# CC2340R5 register map
File version: 1.0
CPU: CM0P 1.0, other endian, MPU, FPU, 3 interrupt priority bits
Registers are 32-bit, read-write, reset 0x0 unless marked. A register's access mark holds for its fields unless they carry their own. Offsets are from the block's base; [hi:lo] are bit positions; {n}, {i} and the like mark numbered series; 'fields as' and 'values as' point back to an identical list.

## LGPT0 — This component is a general purpose timer. The timer offers - generation of waveforms and events. - capture of signal period and duty cycle. - generation of IR signals. - decoding of quadrature encoded signals. - motor control features. It consists of a - 16-bit counter. - 8-bit prescaler - 3 capture compare channels. - 3 event outputs. - 3 capture inputs. Each channel subscribes to the synchronous event bus. They can control one or more event outputs in both capture and compare modes. PRECFG.TICKSRC selects tick source for the timer.
Base 0x40060000
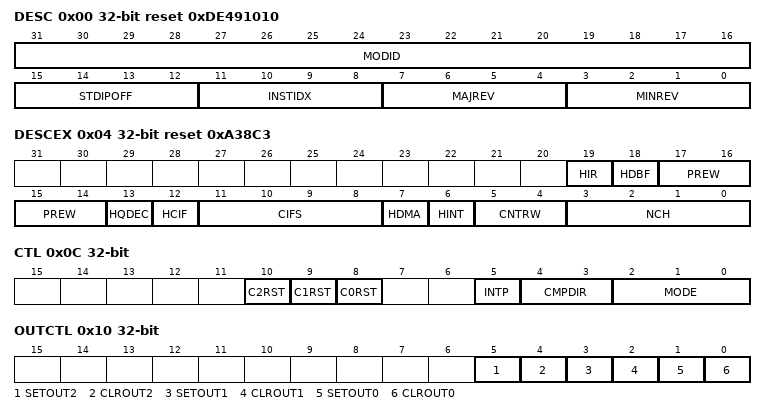
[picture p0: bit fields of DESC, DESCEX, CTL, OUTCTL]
0x00 DESC reset 0xDE491010 — Description Register. This register provides IP module ID, revision information, instance index and standard MMR registers offset.
  [31:16] MODID ro — [31:16] Module identifier used to uniquely identify this IP.
  [15:12] STDIPOFF ro — [15:12] Standard IP MMR block offset. Standard IP MMRs are the set of from aggregated IRQ registers till DTB. 0: Standard IP MMRs do not exist 0x1-0xF: Standard IP MMRs begin at offset of (64*STDIPOFF from the base IP address)
  [11:8] INSTIDX ro — [11:8] IP Instance ID number. If multiple instances of IP exist in the device, this field can identify the instance number.
  [7:4] MAJREV ro — [7:4] Major revision of IP.
  [3:0] MINREV ro — [3:0] Minor revision of IP.
0x04 DESCEX reset 0xA38C3 — Description Extended This register describes the parameters of the LGPT.
  [19] HIR ro — [19:19] Has IR logic.
  [18] HDBF ro — [18:18] Has Dead-Band, Fault, and Park logic.
  [17:14] PREW ro — [17:14] Prescale width. The prescaler can maximum be configured to 2^PREW-1.
  [13] HQDEC ro — [13:13] Has Quadrature Decoder.
  [12] HCIF ro — [12:12] Has channel input filter.
  [11:8] CIFS ro — [11:8] Channel input filter size. The prevailing state filter can maximum be configured to 2^CIFS-1.
  [7] HDMA ro — [7:7] Has uDMA output and logic.
  [6] HINT ro — [6:6] Has interrupt output and logic.
  [5:4] CNTRW ro — [5:4] Counter bit-width. The maximum counter value is equal to 2^CNTRW-1.
    2=CNTR32 (32-bit counter.); 1=CNTR24 (24-bit counter.); 0=CNTR16 (16-bit counter.)
  [3:0] NCH ro — [3:0] Number of channels.
0x08 STARTCFG — Start Configuration This register is only for when CTL.MODE is configured to one of the SYNC modes. This register defines when this LGPT starts.
  [1:0] LGPT0 — [1:0] LGPT start
    0=EV_SYNC (LGPT starts when synchronized event input is high. Configured here EVTSVT.LGPTSYNCSEL.)
0x0C CTL — Timer Control
  [10] C2RST wo — [10:10] Channel 2 reset.
    1=RST (Reset C2CC, PC2CC, and C2CFG.); 0=NOEFF (No effect.)
  [9] C1RST wo — [9:9] Channel 1 reset.
    1=RST (Reset C1CC, PC1CC, and C1CFG.); 0=NOEFF (No effect.)
  [8] C0RST wo — [8:8] Channel 0 reset.
    1=RST (Reset C0CC, PC0CC, and C0CFG.); 0=NOEFF (No effect.)
  [5] INTP — [5:5] Interrupt Phase. This bit field controls when the RIS.TGT and RIS.ZERO interrupts are set.
    1=LATE (RIS.TGT and RIS.ZERO are set one timer clock cycle after CNTR = TARGET/ZERO.); 0=EARLY (RIS.TGT and RIS.ZERO are set one system clock cycle after CNTR = TARGET/ZERO.)
  [4:3] CMPDIR — [4:3] Compare direction. This bit field controls the direction the counter must have in order to set the RIS compare interrupts.
    2=DOWN (Compare RIS fields are only set on down count.); 1=UP (Compare RIS fields are only set on up count.); 0=BOTH (Compare RIS fields are set on up count and down count.)
  [2:0] MODE — [2:0] Timer mode control The CNTR restarts from 0 when MODE is written to UP_ONCE, UP_PER, UPDWN_PER, QDEC, SYNC_UP_ONCE, SYNC_UP_PER or SYNC_UPDWN_PER. When writing MODE all internally queued updates to the channels and TGT is cleared. When configuring the timer, MODE should be the last thing to configure. If changing timer configuration after MODE has been set is necessary, instructions, if any, given in the configuration registers should be followed. See for example C0CFG.
    7=SYNC_UPDWN_PER (Start counting up and down periodically synchronous to another LGPT, selected within STARTCFG. The timer is started by setting CTL.MODE = UPDWN_PER automatically. It then operates as a normal timer in CTL.MODE = UPDWN_PER, counting from 0 to target value and back to 0, repeatedly. Period = (target value * 2) * timer clock period); 6=SYNC_UP_PER (Start counting up periodically synchronous to another LGPT, selected within STARTCFG. The timer is started by setting CTL.MODE = UP_PER automatically. It then operates as a normal timer in CTL.MODE = UP_PER, incrementing from 0 to target value, repeatedly. Period = (target value * 2) * timer clock period); 5=SYNC_UP_ONCE (Start counting up once synchronous to another LGPT, selected within STARTCFG. The timer is started by setting CTL.MODE = UP_ONCE automatically. It then functions as a normal timer in CTL.MODE = UP_ONCE, incrementing from 0 to target value, then stops and sets MODE to DIS.); 4=QDEC (The timer functions as a quadrature decoder. IOC input 0, IOC input 1 and IOC input 2 are used respectivly as PHA, PHB and IDX inputs. IDX can be turned off by setting C2CFG.EDGE = NONE. The timer clock frequency sets the sample rate of the QDEC logic. This frequency can be configured in PRECFG.); 3=UPDWN_PER (Count up and down periodically. The timer counts from 0 to target value and back to 0, repeatedly. Period = (target value * 2) * timer clock period); 2=UP_PER (Count up periodically. The timer increments from 0 to target value, repeatedly. Period = (target value + 1) * timer clock period); 1=UP_ONCE (Count up once. The timer increments from 0 to target value, then stops and sets MODE to DIS.); 0=DIS (Disable timer. Updates to counter, channels, and events stop.)
0x10 OUTCTL — Output Control Set and clear individual outputs manually. Manual update of an output takes priority over automatic channel updates to the same output. It is not possible to set and clear an output at the same time, such requests will be neglected. An output can be automatically cleared, set, toggled, or pulsed by each channel, listed in decreasing order of priority. The action with highest priority happens when multiple channels want to update an output at the same time. All outputs are connected to the event fabric and the IO controller. The outputs going to the IO controller have an aditional complementary output, this output is the inverted IO output. Both the IO and the IO complementary outputs are passed through an IO Controller, see IOCTL.
  [5] SETOUT2 wo — [5:5] Set output 2. Write 1 to set output 2.
  [4] CLROUT2 wo — [4:4] Clear output 2. Write 1 to clear output 2.
  [3] SETOUT1 wo — [3:3] Set output 1. Write 1 to set output 1.
  [2] CLROUT1 wo — [2:2] Clear output 1. Write 1 to clear output 1.
  [1] SETOUT0 wo — [1:1] Set output 0. Write 1 to set output 0.
  [0] CLROUT0 wo — [0:0] Clear output 0. Write 1 to clear output 0.
0x14 CNTR — Counter The counter of this timer. After CTL.MODE is set the counter updates at the rate specified in PRECFG.
  [15:0] VAL — [15:0] Current counter value. If CTL.MODE = QDEC this can be used to set the initial counter value during QDEC.
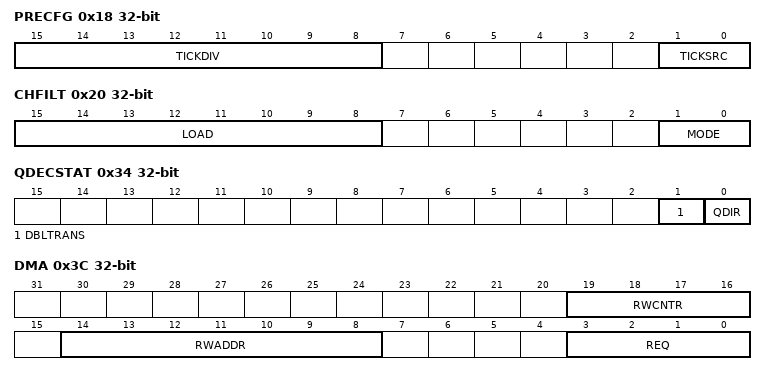
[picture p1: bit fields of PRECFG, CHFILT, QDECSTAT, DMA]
0x18 PRECFG — Clock Prescaler Configuration This register is used to set the timer clock period. The prescaler is a counter which counts down from the value TICKDIV. When the prescaler counter reaches zero, CNTR is updated. The field TICKDIV effectively divides the prescaler tick source. The timer clock frequency can be calculated as TICKSRC/(TICKDIV+1).
  [15:8] TICKDIV — [15:8] Tick division. TICKDIV determines the timer clock frequency for the counter, and timer output updates. The timer clock frequency is the clock selected by TICKSRC divided by (TICKDIV + 1). This inverse is the timer clock period. 0x00: Divide by 1. 0x01: Divide by 2. ... 0xFF: Divide by 256.
  [1:0] TICKSRC — [1:0] Prescaler tick source. TICKSRC determines the source which decrements the prescaler.
    3=BOTH_TICK (Prescaler is updated at both edges of TICKEN.); 2=FALL_TICK (Prescaler is updated at the falling edge of TICKEN.); 1=RISE_TICK (Prescaler is updated at the rising edge of TICKEN.); 0=CLK (Prescaler is updated at the system clock.)
0x1C PREEVENT — Prescaler Event This register is used to output a logic high signal before the zero crossing of the prescaler counter. The output is routed to the IOC.
  [7:0] VAL — [7:0] Sets the HIGH time of the prescaler event output. Event goes high when the prescaler counter equals VAL. Event goes low when prescaler counter is 0. Note: - Can be used to precharge or turn an external component on for a short time before sampling, like in QDEC. - If there is a requirement to create such events that have very short periods compared to timer clock period, use two timers. One timer acts as prescaler and event generator for another timer.
0x20 CHFILT — Channel Input Filter This register is used to configure the filter on the channel inputs. The configuration is for all inputs. The filter is enabled when a channel is in capture mode. The input to the filter is passed to the edge detection logic if LOAD + 1 consecutive input samples are equal. The filter functions as a down counter, counting down every input sample. If two consecutive samples are unequal, the filter counter restarts from LOAD. If the filter counter reaches zero, the input signal is valid and passed to the edge detection logic. The channel filter should only be configured while the CTL.MODE = DIS. Configuring the filter while the timer is running can result in unexpected behavior.
  [15:8] LOAD — [15:8] The input of the channel filter is passed to the edge detection logic after LOAD + 1 consecutive equal samples.
  [1:0] MODE — [1:0] Channel filter mode
    3=TIMERCLK (Filter is clocked by timer clock.); 2=TICKSRC (Filter is clocked by PRECFG.TICKSRC.); 1=CLK (Filter is clocked by system clock.); 0=BYPASS (Filter is bypassed. No Filter is used.)
0x34 QDECSTAT — Quadrature Decoder Status This register can be used during QDEC mode to check the status of the quadrature decoder.
  [1] DBLTRANS ro — [1:1] Double transition
    1=DBL (Double transition on phase inputs.); 0=NONE (Single or no transition on phase inputs.)
  [0] QDIR ro — [0:0] Direction of count during QDEC mode.
    1=DOWN (Down (PHB leads PHA)); 0=UP (Up (PHA leads PHB))
0x38 IRGEN — IR Generation Use this register to generate IR codes. When CTL = 1, an AND gate is enabled between IO output 0 in LGPT0 and IC output 0 in LGPT1. The output of the gate overrides IO output 0 in LGPT0. See OUTCTL for explanation of outputs. To generate IR codes let LGPT0 generate the carrier wave on output 0. Set this output as tick input of LGPT1, with PRECFG.TICKSRC = FALL_TICK. Generate wanted IR codes by adjusting LGPT1 PTGT and PC0CC.
  [0] CTL — [0:0] Control
    1=EN (Enable.); 0=DIS (Disable.)
0x3C DMA — Direct Memory Accsess This register is used to enable DMA requests from the timer and set the register addresses which the DMA will access (read/write). Choose DMA request source by setting the REQ field. The setting of the corresponding interrupt in the RIS registers also sets the DMA request. Upon a DMA request defined by REQ an internal address pointer is set to RWADDR*4. Every access to DMARW will increment the internal pointer by 4 such that the next DMA access will be to the next register. The internal pointer will stop after RWCNTR increments. Further access will be ignored.
  [19:16] RWCNTR — [19:16] The read/write counter. RWCNTR+1 is the number of times the DMA can access (read/write) the DMARW register. For each DMA access to DMARW an internal counter is incremented, writing to the next address field. RWADDR + 4*RWCNTR is the final register address which can be accessed by the DMA.
  [14:8] RWADDR — [14:8] The base address which the DMA access when reading/writing DMARW. The base address is set by taking the 9 LSB of the physical address and divide by 4. For example, if you wanted the RWADDR to point to the PTGT register you should set RWADDR = 0x0FC/4.
  [3:0] REQ
    {v}=C{v-4}CC (Setting of RIS.C{v-4}CC generates a DMA request.) (v=4..15); 3=FAULT (Setting of RIS.FAULT generates a DMA request.); 2=ZERO (Setting of RIS.ZERO generates a DMA request.); 1=TGT (Setting of RIS.TGT generates a DMA request.); 0=DIS (Disabled)
0x40 DMARW — Direct Memory Access This register is used by the DMA to access (read/write) register inside this LGPT module. Each access to this register will increment the internal DMA address counter. See DMA for description.
  [15:0] VAL — [15:0] DMA read write value. The value that is read/written from/to the registers.
0x44 ADCTRG — ADC Trigger This register is used to enable ADC trigger from the timer. Choose ADC trigger source by setting the SRC field. The setting of the corresponding interrupt in the RIS registers also sets the ADC trigger.
  [3:0] SRC
    {v}=C{v-4}CC (Setting of RIS.C{v-4}CC generates an ADC trigger.) (v=4..15); 3=FAULT (Setting of RIS.FAULT generates an ADC trigger.); 2=ZERO (Setting of RIS.ZERO generates an ADC trigger.); 1=TGT (Setting of RIS.TGT generates an ADC trigger.); 0=DIS (Disabled)
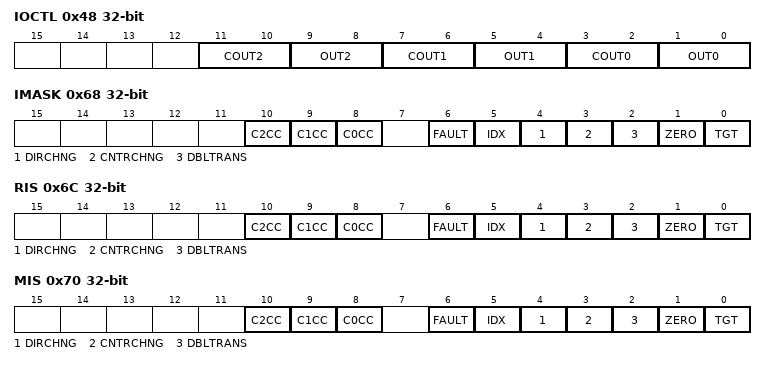
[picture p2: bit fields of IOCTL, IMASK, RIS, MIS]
0x48 IOCTL — IO Controller This register controls the IO outputs.
  [11:10] COUT2 — [11:10] IO complementary output 2 control This bit field controls IO complementary output 2.
    3=INV (Inverted value. The IO complementary output is inverted.); 2=HIGH (Driven high. The IO complementary output is driven high.); 1=LOW (Driven low. The IO complementary output is driven low.); 0=NRM (Normal output. The IO complementary output is not changed.)
  [9:8] OUT2 — [9:8] IO output 2 control This bit field controls IO output 2.
    3=INV (Inverted value. The IO output is inverted.); 2=HIGH (Driven high. The IO output is driven high.); 1=LOW (Driven low. The IO output is driven low.); 0=NRM (Normal output. The IO output is not changed.)
  [7:6] COUT1 — [7:6] IO complementary output 1 control This bit field controls IO complementary output 1.
    values as COUT2
  [5:4] OUT1 — [5:4] IO output 1 control This bit field controls IO output 1.
    values as OUT2
  [3:2] COUT0 — [3:2] IO complementary output 0 control This bit field controls IO complementary output 0.
    values as COUT2
  [1:0] OUT0 — [1:0] IO output 0 control This bit field controls IO output 0.
    values as OUT2
0x68 IMASK — Interrupt mask. This register selects interrupt sources which are allowed to pass from RIS to MIS when the corresponding bit-fields are set to 1.
  [all] fields
    1=EN (Enable); 0=DIS (Disable)
  [10] C2CC — [10:10] Enable RIS.C2CC interrupt.
  [9] C1CC — [9:9] Enable RIS.C1CC interrupt.
  [8] C0CC — [8:8] Enable RIS.C0CC interrupt.
  [6] FAULT — [6:6] Enable RIS.FAULT interrupt.
  [5] IDX — [5:5] Enable RIS.IDX interrupt.
  [4] DIRCHNG — [4:4] Enable RIS.DIRCHNG interrupt.
  [3] CNTRCHNG — [3:3] Enable RIS.CNTRCHNG interrupt.
  [2] DBLTRANS — [2:2] Enable RIS.DBLTRANS interrupt.
  [1] ZERO — [1:1] Enable RIS.ZERO interrupt.
  [0] TGT — [0:0] Enable RIS.TGT interrupt.
0x6C RIS — Raw interrupt status. This register reflects the state of all pending interrupts, regardless of masking. This register allows the user to implement a poll scheme. A flag set in this register can be cleared by writing 1 to the corresponding ICLR register bit.
  [all] fields
    1=SET; 0=CLR (Cleared)
  [10] C2CC ro — [10:10] Status of the C2CC interrupt. The interrupt is set when C2CC has capture or compare event.
  [9] C1CC ro — [9:9] Status of the C1CC interrupt. The interrupt is set when C1CC has capture or compare event.
  [8] C0CC ro — [8:8] Status of the C0CC interrupt. The interrupt is set when C0CC has capture or compare event.
  [6] FAULT ro — [6:6] Status of the FAULT interrupt. The interrupt is set immediately on active fault input.
  [5] IDX ro — [5:5] Status of the IDX interrupt. The interrupt is set when IDX is active.
  [4] DIRCHNG ro — [4:4] Status of the DIRCHNG interrupt. The interrupt is set when the direction of the counter changes.
  [3] CNTRCHNG ro — [3:3] Status of the CNTRCHNG interrupt. The interrupt is set when the counter increments or decrements.
  [2] DBLTRANS ro — [2:2] Status of the DBLTRANS interrupt. The interrupt is set when a double transition has happened during QDEC mode.
  [1] ZERO ro — [1:1] Status of the ZERO interrupt. The interrupt is set when CNTR = 0.
  [0] TGT ro — [0:0] Status of the TGT interrupt. The interrupt is set when CNTR = TGT.
0x70 MIS — Masked interrupt status. This register is simply a bitwise AND of the contents of IMASK and RIS.*] registers. A flag set in this register can be cleared by writing 1 to the corresponding ICLR register bit.
  [all] fields
    1=SET; 0=CLR (Cleared)
  [10] C2CC ro — [10:10] Masked status of the RIS.C2CC interrupt.
  [9] C1CC ro — [9:9] Masked status of the RIS.C1CC interrupt.
  [8] C0CC ro — [8:8] Masked status of the RIS.C0CC interrupt.
  [6] FAULT ro — [6:6] Masked status of the RIS.FAULT interrupt.
  [5] IDX ro — [5:5] Masked status of the RIS.IDX interrupt.
  [4] DIRCHNG ro — [4:4] Masked status of the RIS.DIRCHNG interrupt.
  [3] CNTRCHNG ro — [3:3] Masked status of the RIS.CNTRCHNG interrupt.
  [2] DBLTRANS ro — [2:2] Masked status of the RIS.DBLTRANS interrupt.
  [1] ZERO ro — [1:1] Masked status of the RIS.ZERO interrupt.
  [0] TGT ro — [0:0] Masked status of the RIS.TGT interrupt.
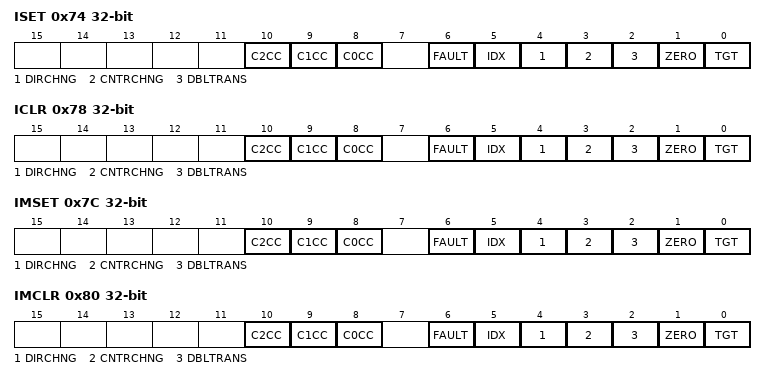
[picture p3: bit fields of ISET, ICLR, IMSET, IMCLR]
0x74 ISET — Interrupt set register. This register can used by software for diagnostics and safety checking purposes. Writing a 1 to a bit in this register will set the event and the corresponding RIS bit also gets set. If the corresponding IMASK bit is set, then the corresponding MIS register bit also gets set.
  [all] fields
    1=SET; 0=NO_EFFECT
  [10] C2CC wo — [10:10] Set the RIS.C2CC interrupt.
  [9] C1CC wo — [9:9] Set the RIS.C1CC interrupt.
  [8] C0CC wo — [8:8] Set the RIS.C0CC interrupt.
  [6] FAULT wo — [6:6] Set the RIS.FAULT interrupt.
  [5] IDX wo — [5:5] Set the RIS.IDX interrupt.
  [4] DIRCHNG wo — [4:4] Set the RIS.DIRCHNG interrupt.
  [3] CNTRCHNG wo — [3:3] Set the RIS.CNTRCHNG interrupt.
  [2] DBLTRANS wo — [2:2] Set the RIS.DBLTRANS interrupt.
  [1] ZERO wo — [1:1] Set the RIS.ZERO interrupt.
  [0] TGT wo — [0:0] Set the RIS.TGT interrupt.
0x78 ICLR — Interrupt clear register. This register allows software to clear interrupts. Writing a 1 to a bit in this register will clear the event and the corresponding RIS bit also gets cleared. If the corresponding IMASK bit is set, then the corresponding MIS register bit also gets cleared.
  [all] fields
    1=CLR (Clear); 0=NO_EFFECT
  [10] C2CC wo — [10:10] Clear the RIS.C2CC interrupt.
  [9] C1CC wo — [9:9] Clear the RIS.C1CC interrupt.
  [8] C0CC wo — [8:8] Clear the RIS.C0CC interrupt.
  [6] FAULT wo — [6:6] Clear the RIS.FAULT interrupt.
  [5] IDX wo — [5:5] Clear the RIS.IDX interrupt.
  [4] DIRCHNG wo — [4:4] Clear the RIS.DIRCHNG interrupt.
  [3] CNTRCHNG wo — [3:3] Clear the RIS.CNTRCHNG interrupt.
  [2] DBLTRANS wo — [2:2] Clear the RIS.DBLTRANS interrupt.
  [1] ZERO wo — [1:1] Clear the RIS.ZERO interrupt.
  [0] TGT wo — [0:0] Clear the RIS.TGT interrupt.
0x7C IMSET — Interrupt mask set register. Writing a 1 to a bit in this register will set the corresponding IMASK bit.
  [all] fields
    1=SET; 0=NO_EFFECT
  [10] C2CC wo — [10:10] Set the MIS.C2CC mask.
  [9] C1CC wo — [9:9] Set the MIS.C1CC mask.
  [8] C0CC wo — [8:8] Set the MIS.C0CC mask.
  [6] FAULT wo — [6:6] Set the MIS.FAULT mask.
  [5] IDX wo — [5:5] Set the MIS.IDX mask.
  [4] DIRCHNG wo — [4:4] Set the MIS.DIRCHNG mask.
  [3] CNTRCHNG wo — [3:3] Set the MIS.CNTRCHNG mask.
  [2] DBLTRANS wo — [2:2] Set the MIS.DBLTRANS mask.
  [1] ZERO wo — [1:1] Set the MIS.ZERO mask.
  [0] TGT wo — [0:0] Set the MIS.TGT mask.
0x80 IMCLR — Interrupt mask clear register. Writing a 1 to a bit in this register will clear the corresponding IMASK bit.
  [all] fields
    1=CLR (Clear); 0=NO_EFFECT
  [10] C2CC wo — [10:10] Clear the MIS.C2CC mask.
  [9] C1CC wo — [9:9] Clear the MIS.C1CC mask.
  [8] C0CC wo — [8:8] Clear the MIS.C0CC mask.
  [6] FAULT wo — [6:6] Clear the MIS.FAULT mask.
  [5] IDX wo — [5:5] Clear the MIS.IDX mask.
  [4] DIRCHNG wo — [4:4] Clear the MIS.DIRCHNG mask.
  [3] CNTRCHNG wo — [3:3] Clear the MIS.CNTRCHNG mask.
  [2] DBLTRANS wo — [2:2] Clear the MIS.DBLTRANS mask.
  [1] ZERO wo — [1:1] Clear the MIS.ZERO mask.
  [0] TGT wo — [0:0] Clear the MIS.TGT mask.
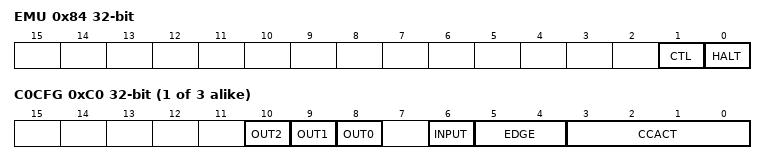
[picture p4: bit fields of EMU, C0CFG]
0x84 EMU — Debug control This register can be used to freeze the timer when CPU halts when HALT is set to 1. When HALT is set to 0, or when the CPU releases debug halt, the filters and edge detection logic is flushed and the timer starts. For setting a predefined output value during a CPU debug halt, PARK, if the timer has this register, should be configured additionally. If this timer does not have the PARK register a predefined output value during CPU halt is not possible.
  [1] CTL — [1:1] Halt control. Configure when the counter shall stop upon CPU halt. This bitfield only applies if HALT = 1.
    1=ZERCOND (Zero condition. The counter stops when CNTR = 0.); 0=IMMEDIATE (Immediate reaction. The counter stops immediately on debug halt.)
  [0] HALT — [0:0] Halt LGPT when CPU is halted in debug.
    1=EN (Enable.); 0=DIS (Disable.)
{0xC0+4i} C{i}CFG (i=0..2) — Channel {i} Configuration This register configures channel function and enables outputs. Each channel has an edge-detection circuit. The the edge-detection circuit is: - enabled while CCACT selects a capture function and CTL.MODE is different from DIS. - flushed while CCACT selects a capture function and CTL.MODE is changed from DIS to another mode. The flush action uses two system clock periods. It prevents capture events caused by expired signal values stored in the edge-detection circuit. The channel input signal enters the edge-detection circuit. False capture events can occur when: - the edge-detection circuit contains expired signal samples and the circuit is enabled without flush as described above. - the CCACT field is reconfigured while CTL.MODE is different from DIS. Primary use scenario is to select CCACT before starting the timer. Follow these steps to configure CCACT to a capture action while CTL.MODE is different from DIS: - Set EDGE to NONE. - Configure CCACT. - Wait for three system clock periods before setting EDGE different from NONE. These steps prevent capture events caused by expired signal values in edge-detection circuit.
  [10] OUT2 — [10:10] Output 2 enable. When 0 $lt; CCACT $lt; 8, OUT2 becomes zero after a capture or compare event.
    1=EN (Channel {i} controls output 2.); 0=DIS (Channel {i} does not control output 2.)
  [9] OUT1 — [9:9] Output 1 enable. When 0 $lt; CCACT $lt; 8, OUT1 becomes zero after a capture or compare event.
    1=EN (Channel {i} controls output 1.); 0=DIS (Channel {i} does not control output 1.)
  [8] OUT0 — [8:8] Output 0 enable. When 0 $lt; CCACT $lt; 8, OUT0 becomes zero after a capture or compare event.
    1=EN (Channel {i} controls output 0.); 0=DIS (Channel {i} does not control output 0.)
  [6] INPUT — [6:6] Select channel input.
    1=IO (IO controller); 0=EV (Event fabric)
  [5:4] EDGE — [5:4] Determines the edge that triggers the channel input event. This happens post filter.
    3=BOTH (Input event is triggered at both edges.); 2=FALL (Input event is triggered at falling edge.); 1=RISE (Input event is triggered at rising edge.); 0=NONE (Input is turned off.)
  [3:0] CCACT — [3:0] Capture-Compare action. Capture-Compare action defines 15 different channel functions that utilize capture, compare, and zero events. In every compare event the timer looks at the current value of CNTR. The corresponding output event will be set 1 timer period after CNTR = C{i}CC.
    15=PULSE_ON_CMP (Pulse on compare repeatedly. Channel function sequence: - Pulse enabled outputs when C{i}CC.VAL = CNTR.VAL. The output is high for two timer clock periods.); 14=TGL_ON_CMP (Toggle on compare repeatedly. Channel function sequence: - Toggle enabled outputs when C{i}CC.VAL = CNTR.VAL.); 13=SET_ON_CMP (Set on compare repeatedly. Channel function sequence: - Set enabled outputs when C{i}CC.VAL = CNTR.VAL.); 12=CLR_ON_CMP (Clear on compare repeatedly. Channel function sequence: - Clear enabled outputs when C{i}CC.VAL = CNTR.VAL.); 11=SET_ON_0_TGL_ON_CMP (Set on zero, toggle on compare repeatedly. Channel function sequence: - Set enabled outputs when CNTR.VAL = 0. - Toggle enabled outputs when C{i}CC.VAL = CNTR.VAL. Set CTL.MODE to UP_PER for edge-aligned PWM generation. Duty cycle is given by: When C{i}CC.VAL $lt;= TGT.VAL: Duty cycle = C{i}CC.VAL / ( TGT.VAL + 1 ). When C{i}CC.VAL $gt; TGT.VAL: Duty cycle = 1. Enabled outputs are cleared when C{i}CC.VAL = 0 and CNTR.VAL = 0.); 10=CLR_ON_0_TGL_ON_CMP (Clear on zero, toggle on compare repeatedly. Channel function sequence: - Clear enabled outputs when CNTR.VAL = 0. - Toggle enabled outputs when C{i}CC.VAL = CNTR.VAL. Set CTL.MODE to UPDWN_PER for center-aligned PWM generation. Duty cycle is given by: When C{i}CC.VAL $lt;= TGT.VAL: Duty cycle = 1 - ( C{i}CC.VAL / TGT.VAL ). When C{i}CC.VAL $gt; TGT.VAL: Duty cycle = 0. Enabled outputs are set when C{i}CC.VAL = 0 and CNTR.VAL = 0.); 9=SET_ON_CAPT (Set on capture repeatedly. Channel function sequence: - Set enabled outputs on capture event and copy CNTR.VAL to C{i}CC.VAL.); 8=PER_PULSE_WIDTH_MEAS (Period and pulse width measurement. Continuously capture period and pulse width of the signal selected by INPUT relative to the signal edge given by EDGE. Set enabled outputs and RIS.C{i}CC when C{i}CC.VAL contains signal period and PC{i}CC.VAL contains signal pulse width. Notes: - Make sure to configure INPUT and CCACT when CTL.MODE equals DIS, then set CTL.MODE to UP_ONCE or UP_PER. - The counter restarts in the selected timer mode when C{i}CC.VAL contains the signal period. - If more than one channel uses this function, the channels will perform this function one at a time. The channel with lowest number has priority and performs the function first. Next measurement starts when current measurement completes successfully or times out. A timeout occurs when counter equals target. - To observe a timeout event the RIS.TGT interrupt can be used, or another channel can be configured to SET_ON_CMP with compare value equal TGT. Signal property requirements: - Signal Period $gt;= 2 * ( 1 + PRECFG.TICKDIV ) * timer clock period. - Signal Period $lt;= MAX(CNTR) * (1 + PRECFG.TICKDIV ) * timer clock period. - Signal low and high phase $gt;= (1 + PRECFG.TICKDIV ) * timer clock period.); 7=PULSE_ON_CMP_DIS (Pulse on compare, and then disable channel. Channel function sequence: - Pulse enabled outputs when C{i}CC.VAL = CNTR.VAL. - Disable channel. The output is high for two timer clock periods.); 6=TGL_ON_CMP_DIS (Toggle on compare, and then disable channel. Channel function sequence: - Toggle enabled outputs when C{i}CC.VAL = CNTR.VAL. - Disable channel.); 5=SET_ON_CMP_DIS (Set on compare, and then disable channel. Channel function sequence: - Set enabled outputs when C{i}CC.VAL = CNTR.VAL. - Disable channel.); 4=CLR_ON_CMP_DIS (Clear on compare, and then disable channel. Channel function sequence: - Clear enabled outputs when C{i}CC.VAL = CNTR.VAL. - Disable channel.); 3=SET_ON_0_TGL_ON_CMP_DIS (Set on zero, toggle on compare, and then disable channel. Channel function sequence: - Set enabled outputs when CNTR.VAL = 0. - Toggle enabled outputs when C{i}CC.VAL = CNTR.VAL. - Disable channel. Enabled outputs are cleared when C{i}CC.VAL = 0 and CNTR.VAL = 0.); 2=CLR_ON_0_TGL_ON_CMP_DIS (Clear on zero, toggle on compare, and then disable channel. Channel function sequence: - Clear enabled outputs when CNTR.VAL = 0. - Toggle enabled outputs when C{i}CC.VAL = CNTR.VAL. - Disable channel. Enabled outputs are set when C{i}CC.VAL = 0 and CNTR.VAL = 0.); 1=SET_ON_CAPT_DIS (Set on capture, and then disable channel. Channel function sequence: - Set enabled outputs on capture event and copy CNTR.VAL to C{i}CC.VAL. - Disable channel. Primary use scenario is to select this function before starting the timer. Follow these steps to select this function while CTL.MODE is different from DIS: - Set CCACT to SET_ON_CAPT with no output enable. - Configure INPUT (optional). - Wait for three timer clock periods as defined in PRECFG before setting CCACT to SET_ON_CAPT_DIS. Output enable is optional. These steps prevent capture events caused by expired signal values in edge-detection circuit.); 0=DIS (Disable channel.)
0xFC PTGT — Pipeline Target A read or write to this register will clear the RIS.ZERO and RIS.TGT interrupt. If CTL.MODE != QDEC. Target value for next counter period. The timer will copy PTGT.VAL to TGT.VAL on the upcoming CNTR zero crossing only if PTGT.VAL has been written. The copy does not happen when restarting the timer. This is useful to avoid period jitter in PWM applications with time-varying period, sometimes referenced as phase corrected PWM. If CTL.MODE = QDEC The CNTR value is updated with VALUE on IDX if the counter is counting down. If the counter is counting up, CNTR is loaded with zero on IDX. In this mode the VALUE is not loaded into TGT on zero crossing.
  [15:0] VAL — [15:0] The pipleline target value.
{0x100+4i} PC{i}CC (i=0..2) — Pipeline Channel {i} Capture Compare
  [15:0] VAL — [15:0] Pipeline Capture Compare value. User defined pipeline compare value or channel-updated capture value. A read or write to this register will clear the RIS.C{i}CC interrupt. Compare mode: An update of VAL will be transferred to C{i}CC.VAL when the next CNTR.VAL is zero and CTL.MODE is different from DIS. This is useful for PWM generation and prevents jitter on the edges of the generated signal. Capture mode: When C{i}CFG.CCACT equals PER_PULSE_WIDTH_MEAS then VAL contains the width of the low or high phase of the selected signal. This is specified by C{i}CFG.EDGE.
0x13C TGT reset 0xFFFF — Target User defined counter target. A read or write to this register will clear the RIS.ZERO and RIS.TGT interrupt.
  [15:0] VAL — [15:0] User defined counter target value.
{0x140+4i} C{i}CC (i=0..2) — Channel {i} Capture Compare
  [15:0] VAL — [15:0] Capture Compare value. User defined compare value or channel-updated capture value. A read or write to this register will clear the RIS.C{i}CC interrupt. Compare mode: VAL is compared against CNTR.VAL and an event is generated as specified by C{i}CFG.CCACT when these are equal. Capture mode: The current counter value is stored in VAL when a capture event occurs. C{i}CFG.CCACT determines if VAL is a signal period or a regular capture value.
0x17C PTGTNC — Pipeline Target No Clear Use this register to read or write to PTGT without clearing the RIS.ZERO and RIS.TGT interrupt.
  [15:0] VAL — [15:0] A read or write to this register will not clear the RIS.TGT interrupt. If CTL.MODE != QDEC. Target value for next counter period. The timer copies VAL to TGT.VAL when CNTR.VAL becomes 0. The copy does not happen when restarting the timer. This is useful to avoid period jitter in PWM applications with time-varying period, sometimes referenced as phase corrected PWM. If CTL.MODE = QDEC. The CNTR.VAL is updated with VAL on IDX. VAL is not loaded into TGT.VAL when CNTR.VAL becomes 0.
{0x180+4i} PC{i}CCNC (i=0..2) — Pipeline Channel {i} Capture Compare No Clear
  [15:0] VAL — [15:0] Pipeline Capture Compare value. User defined pipeline compare value or channel-updated capture value. A read or write to this register will not clear the RIS.C{i}CC interrupt. Compare mode: An update of VAL will be transferred to C{i}CC.VAL when the next CNTR.VAL is zero and CTL.MODE is different from DIS. This is useful for PWM generation and prevents jitter on the edges of the generated signal. Capture mode: When C{i}CFG.CCACT equals PER_PULSE_WIDTH_MEAS then VAL contains the width of the low or high phase of the selected signal. This is specified by C{i}CFG.EDGE.
0x1BC TGTNC reset 0xFFFF — Target No Clear Use this register to read or write to TGT without clearing the RIS.ZERO and RIS.TGT interrupt.
  [15:0] VAL — [15:0] User defined counter target value.
{0x1C0+4i} C{i}CCNC (i=0..2) — Channel {i} Capture Compare No Clear
  [15:0] VAL — [15:0] Capture Compare value. User defined compare value or channel-updated capture value. A read or write to this register will not clear the RIS.C{i}CC interrupt. Compare mode: VAL is compared against CNTR.VAL and an event is generated as specified by C{i}CFG.CCACT when these are equal. Capture mode: The current counter value is stored in VAL when a capture event occurs. C{i}CFG.CCACT determines if VAL is a signal period or a regular capture value.

## LGPT1 — This component is a general purpose timer. The timer offers - generation of waveforms and events. - capture of signal period and duty cycle. - generation of IR signals. - decoding of quadrature encoded signals. - motor control features. It consists of a - 16-bit counter. - 8-bit prescaler - 3 capture compare channels. - 3 event outputs. - 3 capture inputs. Each channel subscribes to the synchronous event bus. They can control one or more event outputs in both capture and compare modes. PRECFG.TICKSRC selects tick source for the timer.
Base 0x40061000
Registers as LGPT0, without QDECSTAT, IRGEN; these are added or differ:
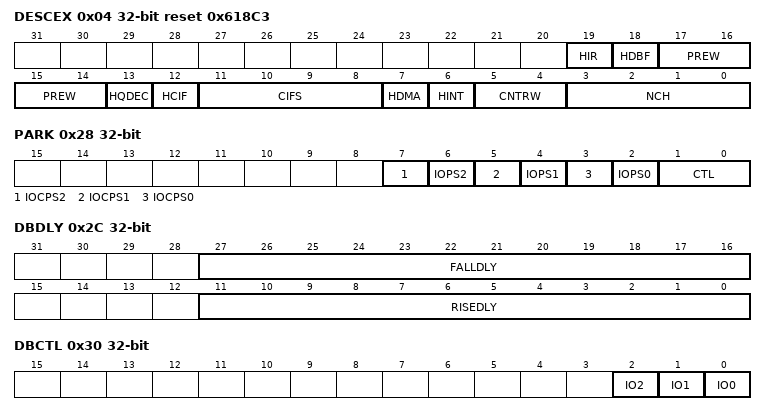
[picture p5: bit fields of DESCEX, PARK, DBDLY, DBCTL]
0x04 DESCEX reset 0x618C3 — Description Extended This register describes the parameters of the LGPT.
  fields as LGPT0.DESCEX
0x08 STARTCFG — Start Configuration This register is only for when CTL.MODE is configured to one of the SYNC modes. This register defines when this LGPT starts.
  [1:0] LGPT0 — [1:0] LGPT start
    0=EV_SYNC (LGPT starts when synchronized event input is high. Configured here EVTSVT.LGPTSYNCSEL.)
0x24 FAULT — Fault This register is used to configure the fault input logic. Primary use scenario is to select CTL before starting the timer. Follow these steps to configure CTL while CTL.MODE is different from DIS: - Set C0CFG.EDGE to NONE. - Configure CTL. - Wait for three system clock periods before setting C0CFG.EDGE different from NONE. These steps prevent fault detection caused by expired signal values in synchronizers and edge-detection circuit.
  [1:0] CTL — [1:0] Fault control On active fault input the counter can optionally stop. If the counter stops this is done by hardware, software must then restart the timer if wanted. The fault input overrides channel 0 IOC input when CTL != DIS. This means that channel 0 receives fault as input signal when C0CFG.INPUT = IO and CTL != DIS. CHFILT can be used to avoid glitching on the fault input. Fault is level triggered, the polarity is set by the C0CFG.EDGE field. Here C0CFG.EDGE = RISE gives active high and C0CFG.EDGE = FALL gives active low polarity. Fault is typically used together with PARK to stop the PWM signal to an external motor control circuit safely. Configure PARK to ensure predefined values of the PWM outputs. If CTL != DIS the RIS.FAULT interrupt is set immediately when the fault input is active while CTL.MODE != DIS. The three modes of fault is described below: CTL = IMMEDIATE In this mode the counter stops immediately on an active fault input. This is done by hardware by setting CTL.MODE = DIS. To start the counter software must set CTL.MODE != DIS. When the counter has stopped, the input synchronizers and the channel filter is not running. This means that if RIS.FAULT is cleared it will not be set again while CTL.MODE = DIS. CTL = ZEROCOND In this mode the counter stops when CNTR = 0 after an active fault input. If the RIS.FAULT interrupt has been cleared by software before CNTR = 0, and the fault input is inactive, the counter will continue as normal. When the counter stops on zero, it can be started again by clearing the RIS.FAULT interrupt if the fault input is inactive. To change the counter mode set CTL.MODE = DIS, clear the RIS.FAULT interrupt, then start timer in wanted mode. CTL = IRQ In this mode only the RIS.FAULT flag is set on an active fault input.
    3=IRQ (Interrupt request. Only set RIS.FAULT on active fault.); 2=ZERCOND (Zero condition. The counter stops when CNTR = 0.); 1=IMMEDIATE (Immediate reaction. The counter stops immediately on fault.); 0=DIS (Disable. The timer ignores fault.)
0x28 PARK — Park This register configures how the outputs should be set in Park mode. Park mode is either entered by debug halt or fault. Park mode is activated when the counter stops. Park mode is inactive when the counter starts. When park mode is active all outputs are set to their predefined states. For IO output signals which have enabled dead band, a dead band insertion will be done before switching to the predefined state.
  [7] IOCPS2 — [7:7] IO Complementary Park State 2 Park state for IO Complementary output 2.
    1=HIGH (Output is set high in park mode.); 0=LOW (Output is set low in park mode.)
  [6] IOPS2 — [6:6] IO Park State 2 Park state for IO output 2.
    values as IOCPS2
  [5] IOCPS1 — [5:5] IO Complementary Park State 1 Park state for IO Complementary output 1.
    values as IOCPS2
  [4] IOPS1 — [4:4] IO Park State 1 Park state for IO output 1.
    values as IOCPS2
  [3] IOCPS0 — [3:3] IO Complementary Park State 0 Park state for IO Complementary output 0.
    values as IOCPS2
  [2] IOPS0 — [2:2] IO Park State 0 Park state for IO output 0.
    values as IOCPS2
  [1:0] CTL — [1:0] Park Control.
    3=BOTH (Enter parkmode on fault or debug.); 2=DEBUG (Enter park mode on debug.); 1=FAULT (Enter park mode on fault.); 0=DIS (Disable park mode.)
0x2C DBDLY — Dead Band Delay This register is used to insert a dead band delay when generating complementary PWM signals. To enable dead band, on for example IO output 0, create a reference PWM signal on Output 0, then set DBCTL.IOC0 = EN. TBD: 12-bit width fall delay and rise delay may be excessive, if 8-bits are enough we can join DBDLY and DBCTL.
  [27:16] FALLDLY — [27:16] Fall delay. The number of system clock periods inserted between the fall of the dead band reference signal and the rise of the inverted output signal.
  [11:0] RISEDLY — [11:0] Rise delay. The number of system clock periods inserted between the rise of the dead band reference signal and the rise of the output signal.
0x30 DBCTL — Dead Band Control This register is used to enable dead band for IOC outputs.
  [all] fields
    1=EN (Enable); 0=DIS (Disable)
  [2] IO2 — [2:2] Enable dead band on IO and IO complementary output 2.
  [1] IO1 — [1:1] Enable dead band on IO and IO complementary output 1.
  [0] IO0 — [0:0] Enable dead band on IO and IO complementary output 0.

## LGPT2 — This component is a general purpose timer. The timer offers - generation of waveforms and events. - capture of signal period and duty cycle. - generation of IR signals. - decoding of quadrature encoded signals. - motor control features. It consists of a - 16-bit counter. - 8-bit prescaler - 3 capture compare channels. - 3 event outputs. - 3 capture inputs. Each channel subscribes to the synchronous event bus. They can control one or more event outputs in both capture and compare modes. PRECFG.TICKSRC selects tick source for the timer.
Base 0x40062000
Registers as LGPT0, without IRGEN; these are added or differ:
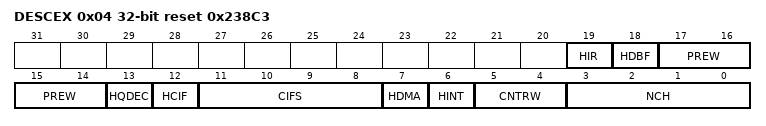
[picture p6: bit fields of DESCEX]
0x04 DESCEX reset 0x238C3 — Description Extended This register describes the parameters of the LGPT.
  fields as LGPT0.DESCEX
0x08 STARTCFG — Start Configuration This register is only for when CTL.MODE is configured to one of the SYNC modes. This register defines when this LGPT starts.
  [1:0] LGPT0 — [1:0] LGPT start
    0=EV_SYNC (LGPT starts when synchronized event input is high. Configured here EVTSVT.LGPTSYNCSEL.)

## LGPT3 — This component is a general purpose timer. The timer offers - generation of waveforms and events. - capture of signal period and duty cycle. - generation of IR signals. - decoding of quadrature encoded signals. - motor control features. It consists of a - 16-bit counter. - 8-bit prescaler - 3 capture compare channels. - 3 event outputs. - 3 capture inputs. Each channel subscribes to the synchronous event bus. They can control one or more event outputs in both capture and compare modes. PRECFG.TICKSRC selects tick source for the timer.
Base 0x40063000
Registers as LGPT1, without FAULT, PARK, DBDLY, DBCTL; these are added or differ:
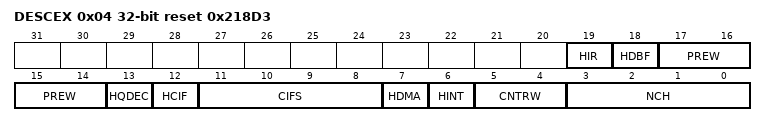
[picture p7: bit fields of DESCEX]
0x04 DESCEX reset 0x218D3 — Description Extended This register describes the parameters of the LGPT.
  fields as LGPT0.DESCEX
0x14 CNTR — Counter The counter of this timer. After CTL.MODE is set the counter updates at the rate specified in PRECFG.
  [23:0] VAL — [23:0] Current counter value. If CTL.MODE = QDEC this can be used to set the initial counter value during QDEC.
0x40 DMARW — Direct Memory Access This register is used by the DMA to access (read/write) register inside this LGPT module. Each access to this register will increment the internal DMA address counter. See DMA for description.
  [23:0] VAL — [23:0] DMA read write value. The value that is read/written from/to the registers.
0xFC PTGT — Pipeline Target A read or write to this register will clear the RIS.ZERO and RIS.TGT interrupt. If CTL.MODE != QDEC. Target value for next counter period. The timer will copy PTGT.VAL to TGT.VAL on the upcoming CNTR zero crossing only if PTGT.VAL has been written. The copy does not happen when restarting the timer. This is useful to avoid period jitter in PWM applications with time-varying period, sometimes referenced as phase corrected PWM. If CTL.MODE = QDEC The CNTR value is updated with VALUE on IDX if the counter is counting down. If the counter is counting up, CNTR is loaded with zero on IDX. In this mode the VALUE is not loaded into TGT on zero crossing.
  [23:0] VAL — [23:0] The pipleline target value.
{0x100+4i} PC{i}CC (i=0..2) — Pipeline Channel {i} Capture Compare
  [23:0] VAL — [23:0] Pipeline Capture Compare value. User defined pipeline compare value or channel-updated capture value. A read or write to this register will clear the RIS.C{i}CC interrupt. Compare mode: An update of VAL will be transferred to C{i}CC.VAL when the next CNTR.VAL is zero and CTL.MODE is different from DIS. This is useful for PWM generation and prevents jitter on the edges of the generated signal. Capture mode: When C{i}CFG.CCACT equals PER_PULSE_WIDTH_MEAS then VAL contains the width of the low or high phase of the selected signal. This is specified by C{i}CFG.EDGE.
0x13C TGT reset 0xFFFFFF — Target User defined counter target. A read or write to this register will clear the RIS.ZERO and RIS.TGT interrupt.
  [23:0] VAL — [23:0] User defined counter target value.
{0x140+4i} C{i}CC (i=0..2) — Channel {i} Capture Compare
  [23:0] VAL — [23:0] Capture Compare value. User defined compare value or channel-updated capture value. A read or write to this register will clear the RIS.C{i}CC interrupt. Compare mode: VAL is compared against CNTR.VAL and an event is generated as specified by C{i}CFG.CCACT when these are equal. Capture mode: The current counter value is stored in VAL when a capture event occurs. C{i}CFG.CCACT determines if VAL is a signal period or a regular capture value.
0x17C PTGTNC — Pipeline Target No Clear Use this register to read or write to PTGT without clearing the RIS.ZERO and RIS.TGT interrupt.
  [23:0] VAL — [23:0] A read or write to this register will not clear the RIS.TGT interrupt. If CTL.MODE != QDEC. Target value for next counter period. The timer copies VAL to TGT.VAL when CNTR.VAL becomes 0. The copy does not happen when restarting the timer. This is useful to avoid period jitter in PWM applications with time-varying period, sometimes referenced as phase corrected PWM. If CTL.MODE = QDEC. The CNTR.VAL is updated with VAL on IDX. VAL is not loaded into TGT.VAL when CNTR.VAL becomes 0.
{0x180+4i} PC{i}CCNC (i=0..2) — Pipeline Channel {i} Capture Compare No Clear
  [23:0] VAL — [23:0] Pipeline Capture Compare value. User defined pipeline compare value or channel-updated capture value. A read or write to this register will not clear the RIS.C{i}CC interrupt. Compare mode: An update of VAL will be transferred to C{i}CC.VAL when the next CNTR.VAL is zero and CTL.MODE is different from DIS. This is useful for PWM generation and prevents jitter on the edges of the generated signal. Capture mode: When C{i}CFG.CCACT equals PER_PULSE_WIDTH_MEAS then VAL contains the width of the low or high phase of the selected signal. This is specified by C{i}CFG.EDGE.
0x1BC TGTNC reset 0xFFFFFF — Target No Clear Use this register to read or write to TGT without clearing the RIS.ZERO and RIS.TGT interrupt.
  [23:0] VAL — [23:0] User defined counter target value.
{0x1C0+4i} C{i}CCNC (i=0..2) — Channel {i} Capture Compare No Clear
  [23:0] VAL — [23:0] Capture Compare value. User defined compare value or channel-updated capture value. A read or write to this register will not clear the RIS.C{i}CC interrupt. Compare mode: VAL is compared against CNTR.VAL and an event is generated as specified by C{i}CFG.CCACT when these are equal. Capture mode: The current counter value is stored in VAL when a capture event occurs. C{i}CFG.CCACT determines if VAL is a signal period or a regular capture value.
